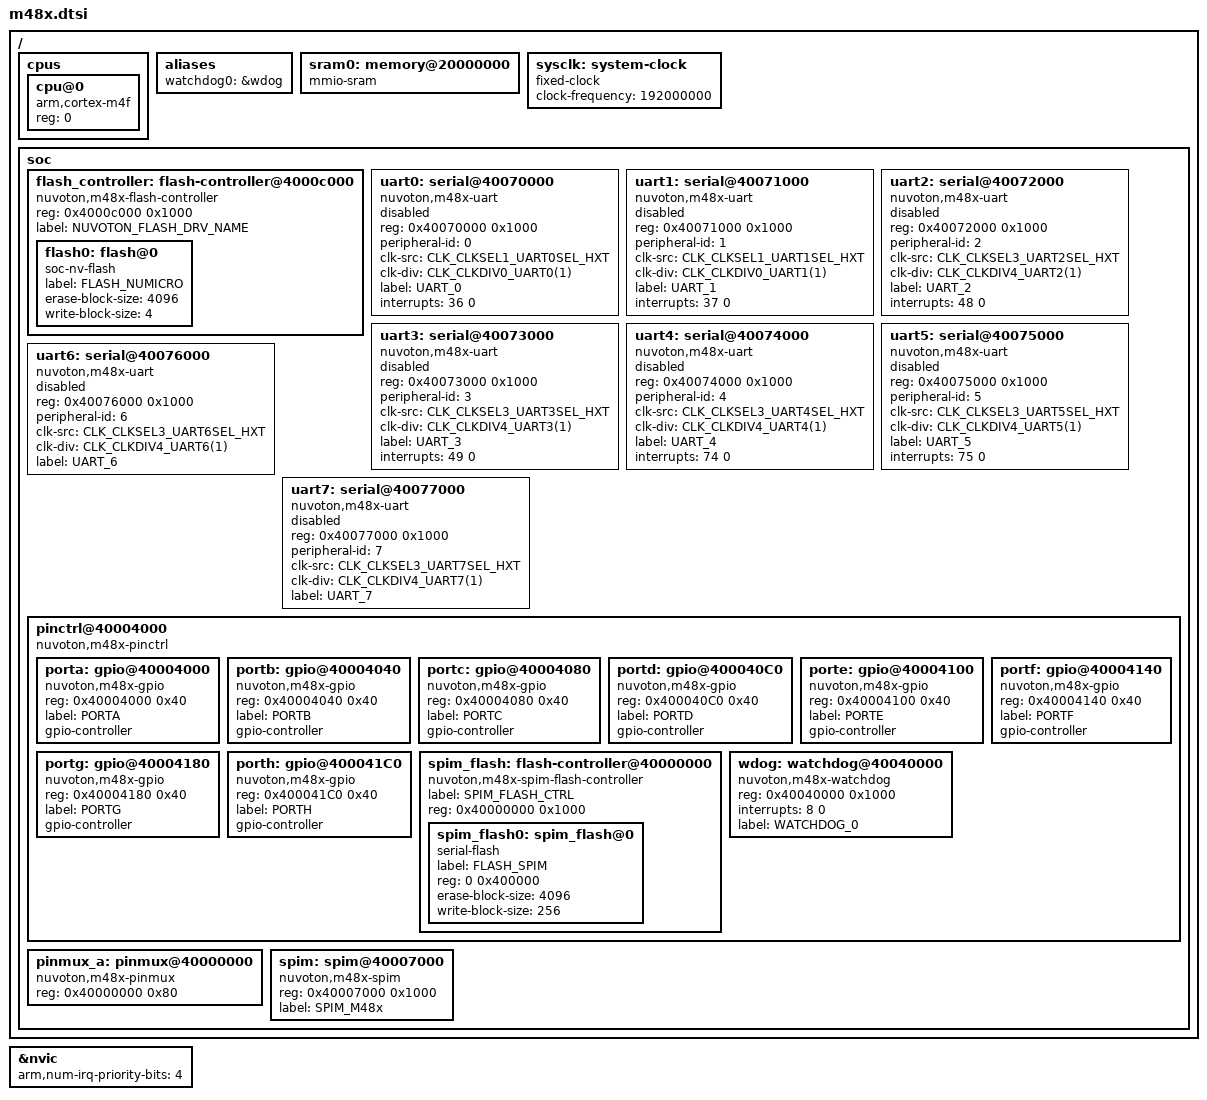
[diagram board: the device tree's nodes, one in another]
#include <arm/armv7-m.dtsi>
#include <mem.h>
#include <dt-bindings/gpio/gpio.h>
#include <zephyr/dt-bindings/clock/m48x.h>
#include <arm/nuvoton/m48x_crypt.dtsi>

/ {
	cpus {
		#address-cells = <1>;
		#size-cells = <0>;

		cpu@0 {
			device_type = "cpu";
			compatible = "arm,cortex-m4f";
			reg = <0>;
		};
	};

	aliases {
		watchdog0 = &wdog;
	};

	/*
	flash0: flash@0 {
        compatible = "serial-flash";
        label = "FLASH_NUMICRO";
        erase-block-size = <4096>;
        write-block-size = <1>;
    };
	*/

	sram0: memory@20000000 {
        compatible = "mmio-sram";
    };

	sysclk: system-clock {
		compatible = "fixed-clock";
		clock-frequency = <192000000>;
		#clock-cells = <0>;
	};

	soc {
		// 0x4000_C000 – 0x4000_CFFF FMC_BA Flash Memory Control Registers
		// TODO: Rename to 'fmc'
		flash_controller: flash-controller@4000c000 {
			compatible = "nuvoton,m48x-flash-controller";
			reg = <0x4000c000 0x1000>;
			//partial-erase;

			#address-cells = <1>;
			#size-cells = <1>;

			label="NUVOTON_FLASH_DRV_NAME";

			flash0: flash@0 {
		        //compatible = "serial-flash";
				compatible = "soc-nv-flash";
		        label = "FLASH_NUMICRO";
		        erase-block-size = <4096>;
		        write-block-size = <4>;
		    };

		};

        /*
        nvmctrl: nvmctrl@41004000  {
            compatible = "nuvoton,m48x-nvmctrl";
            label = "FLASH_CTRL";
            reg = <0x41004000 0x22>;
            interrupts = <5 0>;
            lock-regions = <16>;

            #address-cells = <1>;
            #size-cells = <1>;

            flash0: flash@0 {
                //compatible = "soc-nv-flash";
                compatible = "serial-flash";
                label = "FLASH_0";
                reg = <0 0x40000>;
                write-block-size = <4>;
            };
        };
        */

		uart0: serial@40070000 {
			compatible = "nuvoton,m48x-uart";
			reg = <0x40070000 0x1000>;
            peripheral-id = <0>;
            clk-src = <CLK_CLKSEL1_UART0SEL_HXT>;
            clk-div = <CLK_CLKDIV0_UART0(1)>;
			status = "disabled";
			label = "UART_0";
            interrupts = <36 0>; // UART0_IRQn
		};

		uart1: serial@40071000 {
			compatible = "nuvoton,m48x-uart";
			reg = <0x40071000 0x1000>;
            peripheral-id = <1>;
            clk-src = <CLK_CLKSEL1_UART1SEL_HXT>;
            clk-div = <CLK_CLKDIV0_UART1(1)>;
			status = "disabled";
			label = "UART_1";
            interrupts = <37 0>; // UART1_IRQn
		};

		uart2: serial@40072000 {
			compatible = "nuvoton,m48x-uart";
			reg = <0x40072000 0x1000>;
            peripheral-id = <2>;
            clk-src = <CLK_CLKSEL3_UART2SEL_HXT>;
            clk-div = <CLK_CLKDIV4_UART2(1)>;
			status = "disabled";
			label = "UART_2";
            interrupts = <48 0>; // UART2_IRQn
		};

		uart3: serial@40073000 {
			compatible = "nuvoton,m48x-uart";
			reg = <0x40073000 0x1000>;
            peripheral-id = <3>;
            clk-src = <CLK_CLKSEL3_UART3SEL_HXT>;
            clk-div = <CLK_CLKDIV4_UART3(1)>;
			status = "disabled";
			label = "UART_3";
            interrupts = <49 0>; // UART3_IRQn
		};

		uart4: serial@40074000 {
			compatible = "nuvoton,m48x-uart";
			reg = <0x40074000 0x1000>;
            peripheral-id = <4>;
            clk-src = <CLK_CLKSEL3_UART4SEL_HXT>;
            clk-div = <CLK_CLKDIV4_UART4(1)>;
			status = "disabled";
			label = "UART_4";
            interrupts = <74 0>; // UART4_IRQn
		};

		uart5: serial@40075000 {
			compatible = "nuvoton,m48x-uart";
			reg = <0x40075000 0x1000>;
            peripheral-id = <5>;
            clk-src = <CLK_CLKSEL3_UART5SEL_HXT>;
            clk-div = <CLK_CLKDIV4_UART5(1)>;
			status = "disabled";
			label = "UART_5";
            interrupts = <75 0>; // UART5_IRQn
		};

		uart6: serial@40076000 {
			compatible = "nuvoton,m48x-uart";
			reg = <0x40076000 0x1000>;
            peripheral-id = <6>;
            clk-src = <CLK_CLKSEL3_UART6SEL_HXT>;
            clk-div = <CLK_CLKDIV4_UART6(1)>;
			status = "disabled";
			label = "UART_6";
		};

		uart7: serial@40077000 {
			compatible = "nuvoton,m48x-uart";
			reg = <0x40077000 0x1000>;
            peripheral-id = <7>;
            clk-src = <CLK_CLKSEL3_UART7SEL_HXT>;
            clk-div = <CLK_CLKDIV4_UART7(1)>;
			status = "disabled";
			label = "UART_7";
		};

        pinctrl@40004000 {
            compatible = "nuvoton,m48x-pinctrl";
            #address-cells = <1>;
			#size-cells = <1>;
			/*ranges = <0x40004000 0x40004200 0x40>;*/
            ranges = <0x40004000 0x40004000 0x200>;
            porta: gpio@40004000 {
                compatible = "nuvoton,m48x-gpio";
                reg = <0x40004000 0x40>;
                label = "PORTA";
                gpio-controller;
                #gpio-cells = <2>;
                #nuvoton,pin-cells = <2>;
            };
            portb: gpio@40004040 {
                compatible = "nuvoton,m48x-gpio";
                reg = <0x40004040 0x40>;
                label = "PORTB";
                gpio-controller;
                #gpio-cells = <2>;
                #nuvoton,pin-cells = <2>;
            };
            portc: gpio@40004080 {
                compatible = "nuvoton,m48x-gpio";
                reg = <0x40004080 0x40>;
                label = "PORTC";
                gpio-controller;
                #gpio-cells = <2>;
                #nuvoton,pin-cells = <2>;
            };
            portd: gpio@400040C0 {
                compatible = "nuvoton,m48x-gpio";
                reg = <0x400040C0 0x40>;
                label = "PORTD";
                gpio-controller;
                #gpio-cells = <2>;
                #nuvoton,pin-cells = <2>;
            };
            porte: gpio@40004100 {
                compatible = "nuvoton,m48x-gpio";
                reg = <0x40004100 0x40>;
                label = "PORTE";
                gpio-controller;
                #gpio-cells = <2>;
                #nuvoton,pin-cells = <2>;
            };
            portf: gpio@40004140 {
                compatible = "nuvoton,m48x-gpio";
                reg = <0x40004140 0x40>;
                label = "PORTF";
                gpio-controller;
                #gpio-cells = <2>;
                #nuvoton,pin-cells = <2>;
            };
            portg: gpio@40004180 {
                compatible = "nuvoton,m48x-gpio";
                reg = <0x40004180 0x40>;
                label = "PORTG";
                gpio-controller;
                #gpio-cells = <2>;
                #nuvoton,pin-cells = <2>;
            };
            porth: gpio@400041C0 {
                compatible = "nuvoton,m48x-gpio";
                reg = <0x400041C0 0x40>;
                label = "PORTH";
                gpio-controller;
                #gpio-cells = <2>;
                #nuvoton,pin-cells = <2>;
            };



            /* Dedicated SPI interface to access SPI flashes
        	spi_fiu0: spi@40020000 {
        		compatible = "nuvoton,npcx-spi-fiu";
        		#address-cells = <1>;
        		#size-cells = <0>;
        		reg = <0x40020000 0x2000>;
        		//clocks = <&pcc NPCX_CLOCK_BUS_APB3 NPCX_PWDWN_CTL1 2>;
        		label = "SPI_FIU";
        	};
            */


            spim_flash: flash-controller@40000000 {
                compatible = "nuvoton,m48x-spim-flash-controller";
                label = "SPIM_FLASH_CTRL";
                reg = <0x40000000 0x1000>;
                /* interrupts = <3 0>; */

                #address-cells = <1>;
                #size-cells = <1>;

                spim_flash0: spim_flash@0 {
                    //compatible = "soc-nv-flash";// Not sure is a soc-nv-flash
                    compatible = "serial-flash";// Not sure is a soc-nv-flash
                    label = "FLASH_SPIM";
                    reg = <0 0x400000>;
                    erase-block-size = <4096>;
                    write-block-size = <256>;
                };
            };

			wdog: watchdog@40040000 {
				compatible = "nuvoton,m48x-watchdog";
				reg = <0x40040000 0x1000>;
				interrupts = <8 0>;		// WDT_IRQn
				label = "WATCHDOG_0";
			};


        };

        pinmux_a: pinmux@40000000 {
			compatible = "nuvoton,m48x-pinmux";
			reg = <0x40000000 0x80>;
		};



        spim: spim@40007000 {
    		compatible = "nuvoton,m48x-spim";
            reg = <0x40007000 0x1000>;
    		label = "SPIM_M48x";
    		// erase-block-size = <4096>;
    		// write-block-size = <1>;
    	};



	};
};

&nvic {
	arm,num-irq-priority-bits = <4>;
};
